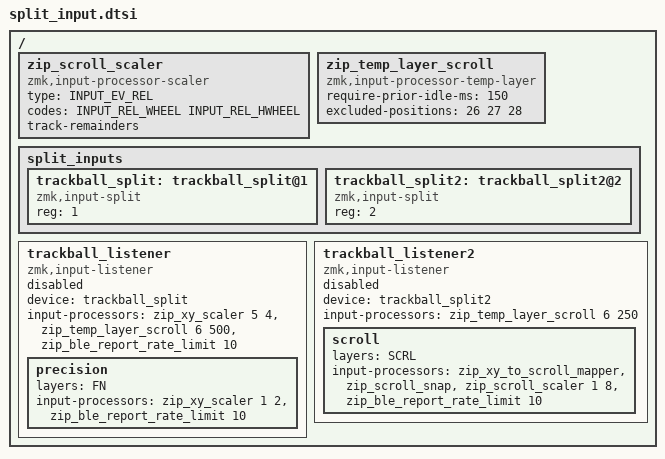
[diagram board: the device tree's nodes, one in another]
#include <scroll-snap.dtsi>
#include <dt-bindings/zmk/input_transform.h>
#include <input/processors.dtsi>
#include <input/processors/report_rate_limit.dtsi>

#define DEF 0
#define NAV 1
#define FN 2
#define NUM 3
#define SYS 4
#define MOUSE 5
#define SCRL 6

/ {
    zip_scroll_scaler: zip_scroll_scaler {
        compatible = "zmk,input-processor-scaler";
        #input-processor-cells = <2>;
        type = <INPUT_EV_REL>;
        codes = <INPUT_REL_WHEEL INPUT_REL_HWHEEL>;
        track-remainders;
    };

    zip_temp_layer_scroll: zip_temp_layer_scroll {
        compatible = "zmk,input-processor-temp-layer";
        #input-processor-cells = <2>;
        require-prior-idle-ms = <150>;
        excluded-positions = <26 27 28>;
    };

    split_inputs {
        #address-cells = <1>;
        #size-cells = <0>;
    
        trackball_split: trackball_split@1 {
            compatible = "zmk,input-split";
            reg = <1>;
        };

        trackball_split2: trackball_split2@2 {
            compatible = "zmk,input-split";
            reg = <2>;
        };
    };

    // RH/Pointer
    trackball_listener: trackball_listener {
        compatible = "zmk,input-listener";
        status = "disabled";
        device = <&trackball_split>;
        input-processors = <&zip_xy_scaler 5 4>, <&zip_temp_layer_scroll 6 500>, <&zip_ble_report_rate_limit 10>;
        
        precision {
            layers = <FN>;
            input-processors = <&zip_xy_scaler 1 2>, <&zip_ble_report_rate_limit 10>;
        };
    };
    
    // LH/Scroll
    trackball_listener2: trackball_listener2 {
        compatible = "zmk,input-listener";
        status = "disabled";
        device = <&trackball_split2>;
        input-processors = <&zip_temp_layer_scroll 6 250>;
                       // , <&zip_ble_report_rate_limit 16>;
                       // , <&zip_x_scaler 0 1>
                       // , <&zip_xy_to_scroll_mapper>
                       // , <&zip_scroll_scaler 1 16>;
    
        scroll {
            layers = <SCRL>;
            input-processors = <&zip_xy_to_scroll_mapper>, <&zip_scroll_snap>, <&zip_scroll_scaler 1 8>, <&zip_ble_report_rate_limit 10>;
            // input-processors = <&zip_x_scaler 0 1>, <&zip_xy_to_scroll_mapper>, <&zip_scroll_scaler 1 10>, <&zip_ble_report_rate_limit 16>;
        };
    };
};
